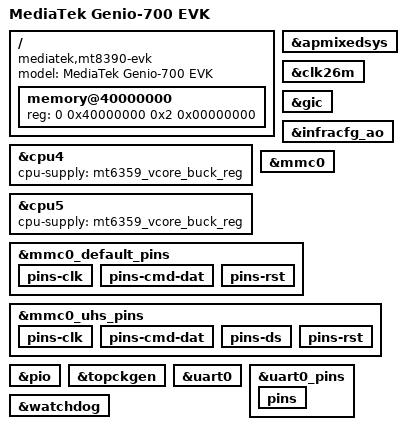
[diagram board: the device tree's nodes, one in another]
// SPDX-License-Identifier: (GPL-2.0 OR MIT)
/*
 * Copyright (C) 2023 MediaTek Inc.
 * Author: Chris Chen <chris-qj.chen@mediatek.com>
 *	   Pablo Sun <pablo.sun@mediatek.com>
 *	   Macpaul Lin <macpaul.lin@mediatek.com>
 */
/dts-v1/;

#include "mt8188.dtsi"
#include "mt8390-genio-common.dtsi"

/ {
	model = "MediaTek Genio-700 EVK";
	compatible = "mediatek,mt8390-evk", "mediatek,mt8390",
		     "mediatek,mt8188";

	memory@40000000 {
		bootph-pre-ram;
		device_type = "memory";
		reg = <0 0x40000000 0x2 0x00000000>;
	};
};

&apmixedsys {
	bootph-pre-ram;
};

&clk26m {
	bootph-pre-ram;
};

&cpu4 {
	cpu-supply = <&mt6359_vcore_buck_reg>;
};

&cpu5 {
	cpu-supply = <&mt6359_vcore_buck_reg>;
};

&gic {
	bootph-pre-ram;
};

&infracfg_ao {
	bootph-pre-ram;
};

&mmc0 {
	bootph-pre-ram;
};

&mmc0_default_pins {
	bootph-pre-ram;

	pins-clk {
		bootph-pre-ram;
	};

	pins-cmd-dat {
		bootph-pre-ram;
	};

	pins-rst {
		bootph-pre-ram;
	};
};

&mmc0_uhs_pins {
	bootph-pre-ram;

	pins-clk {
		bootph-pre-ram;
	};

	pins-cmd-dat {
		bootph-pre-ram;
	};

	pins-ds {
		bootph-pre-ram;
	};

	pins-rst {
		bootph-pre-ram;
	};
};

&pio {
	bootph-pre-ram;
};

&topckgen {
	bootph-pre-ram;
};

&uart0 {
	bootph-pre-ram;
};

&uart0_pins {
	bootph-pre-ram;

	pins {
		bootph-pre-ram;
	};
};

&watchdog {
	bootph-pre-ram;
};
